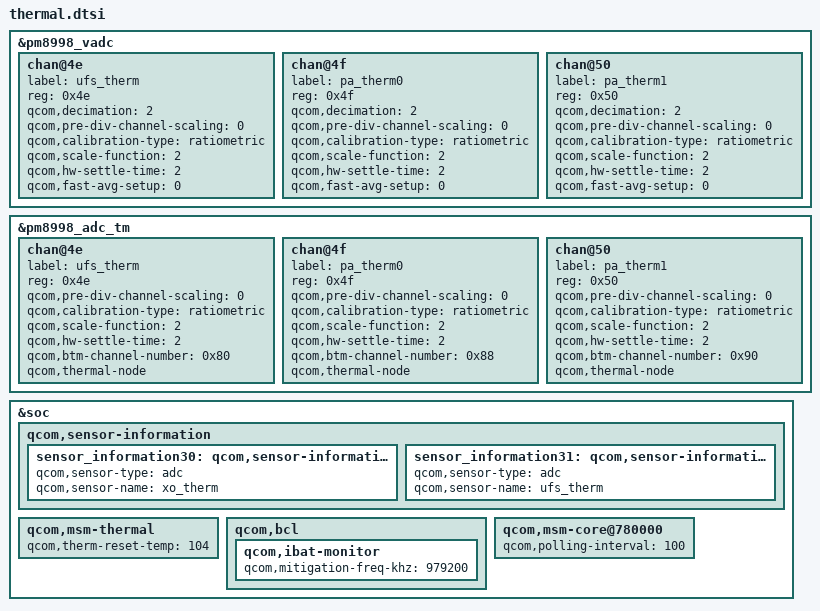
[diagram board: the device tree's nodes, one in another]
&pm8998_vadc {
	chan@4e {
		label = "ufs_therm";
		reg = <0x4e>;
		qcom,decimation = <2>;
		qcom,pre-div-channel-scaling = <0>;
		qcom,calibration-type = "ratiometric";
		qcom,scale-function = <2>;
		qcom,hw-settle-time = <2>;
		qcom,fast-avg-setup = <0>;
	};

	chan@4f {
		label = "pa_therm0";
		reg = <0x4f>;
		qcom,decimation = <2>;
		qcom,pre-div-channel-scaling = <0>;
		qcom,calibration-type = "ratiometric";
		qcom,scale-function = <2>;
		qcom,hw-settle-time = <2>;
		qcom,fast-avg-setup = <0>;
	};

	chan@50 {
		label = "pa_therm1";
		reg = <0x50>;
		qcom,decimation = <2>;
		qcom,pre-div-channel-scaling = <0>;
		qcom,calibration-type = "ratiometric";
		qcom,scale-function = <2>;
		qcom,hw-settle-time = <2>;
		qcom,fast-avg-setup = <0>;
	};
};

&pm8998_adc_tm {
	chan@4e {
		label = "ufs_therm";
		reg = <0x4e>;
		qcom,pre-div-channel-scaling = <0>;
		qcom,calibration-type = "ratiometric";
		qcom,scale-function = <2>;
		qcom,hw-settle-time = <2>;
		qcom,btm-channel-number = <0x80>;
		qcom,thermal-node;
	};

	chan@4f {
		label = "pa_therm0";
		reg = <0x4f>;
		qcom,pre-div-channel-scaling = <0>;
		qcom,calibration-type = "ratiometric";
		qcom,scale-function = <2>;
		qcom,hw-settle-time = <2>;
		qcom,btm-channel-number = <0x88>;
		qcom,thermal-node;
	};

	chan@50 {
		label = "pa_therm1";
		reg = <0x50>;
		qcom,pre-div-channel-scaling = <0>;
		qcom,calibration-type = "ratiometric";
		qcom,scale-function = <2>;
		qcom,hw-settle-time = <2>;
		qcom,btm-channel-number = <0x90>;
		qcom,thermal-node;
	};
};

&soc {
	qcom,sensor-information {
		sensor_information30: qcom,sensor-information-30 {
			qcom,sensor-type = "adc";
			qcom,sensor-name = "xo_therm";
		};
		sensor_information31: qcom,sensor-information-31 {
			qcom,sensor-type = "adc";
			qcom,sensor-name = "ufs_therm";
		};
	};

	qcom,msm-thermal {
		qcom,therm-reset-temp = <104>;
	};

	qcom,bcl {
		qcom,ibat-monitor {
			qcom,mitigation-freq-khz = <979200>;
		};
	};

	qcom,msm-core@780000 {
		qcom,polling-interval = <100>;
	};
};
